# SAMA7G54D1GN0 register map
Vendor: Microchip Technology; Series: SAMA7G5; File version: 0
Registers are 32-bit, read-write, reset 0x0 unless marked. A register's access mark holds for its fields unless they carry their own. Offsets are from the block's base; [hi:lo] are bit positions; {n}, {i} and the like mark numbered series; 'fields as' and 'values as' point back to an identical list.

## ASRC — Asynchronous Sample Rate Converter
Base 0xE1610000
0x00 CR wo — Control Register
  [0] SWRST — Software Reset
    0=No effect; 1=Resets the ASRC
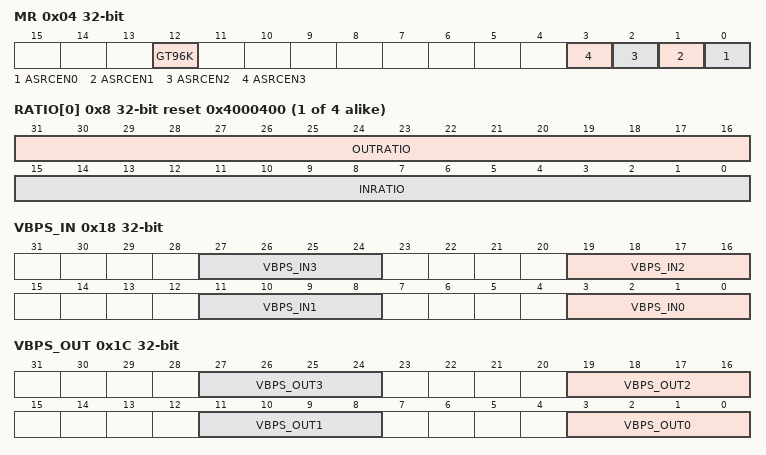
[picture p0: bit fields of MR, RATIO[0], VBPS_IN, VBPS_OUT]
0x04 MR — Mode Register
  [12] GT96K — Frequency Sampling Greater Than 96 kHz
    0=DISABLE (Up to 4 DSP with up to 96 kHz as the upper bound limit of the sampling frequency.); 1=ENABLE (Up to 2 DSP with up to 192 kHz as the upper bound limit of the sampling frequency. The number of enabled DSPs is limited to 2.)
  [n] ASRCEN{n} (n=0..3) — ASRC Stereo Channel {n} Enable
    0=DISABLE (DSPx is disabled.); 1=ENABLE (DSPx is enabled.)
{0x8+4i} RATIO[{i}] (i=0..3) reset 0x4000400 — Ratio Register of Stereo Channel x
  [31:16] OUTRATIO — Output Internal Sampling Rate Ratio
  [15:0] INRATIO — Input Internal Sampling Rate Ratio
0x18 VBPS_IN — Valid Bit Per Sample In Register
  [all] fields
    0=8_BIT (The 8 LSB of THR registers are left aligned on 24-bit data entered to the DSP. The bits [15:8] of the 24-bit data are driven by the 8 LSB of THR registers to increase the dynamic range of the data sent to DSP. The bits [7:0] are driven by 0s.); 1=16_BIT (The 16 LSB of THR registers are left aligned on 24-bit data entered to the DSP. The bits [7:0] of the 24-bit data are driven by the bits [15:8] of the THR registers to increase the dynamic range of the data sent to DSP.); 2=20_BIT (The 20 LSB of THR registers are left aligned on 24-bit data entered to the DSP. The bits [3:0] of the 24-bit data are driven by the bits [19:16] of the THR registers to increase the dynamic range of the data sent to DSP.); 3=24_BIT (The 24 LSB of THR registers are entered to the DSP.); 4=32_BIT (The 24 MSB of THR registers are entered to the DSP.); 5=10_BIT (The 10 LSB of THR registers are left aligned on 24-bit data entered to the DSP. The bits [13:4] of the 24-bit data are driven by the 10 LSB of THR registers to increase the dynamic range of the data sent to DSP. The bits [3:0] are driven by 0s.); 6=12_BIT (The 12 LSB of THR registers are left aligned on 24-bit data entered to the DSP. The bits [11:0] of the 24-bit data are driven by the bits [11:0] of the THR registers to increase the dynamic range of the data sent to DSP.); 7=14_BIT (The 14 LSB of THR registers are left aligned on 24-bit data entered to the DSP. The bits [9:0] of the 24-bit data are driven by the bits [13:4] of the THR registers to increase the dynamic range of the data sent to DSP.); 8=18_BIT (The 18 LSB of THR registers are left aligned on 24-bit data entered to the DSP. The bits [5:0] of the 24-bit data are driven by the bits [17:12] of the THR registers to increase the dynamic range of the data sent to DSP.)
  [8n+3:8n] VBPS_IN{n} (n=0..3) — Valid Bit Per Sample In of DSP {n}
0x1C VBPS_OUT — Valid Bit Per Sample Out Register
  [all] fields
    0=8_BIT (The 8 MSB of the 24-bit read from the DSP output are right-aligned on RHR.); 1=16_BIT (The 16 MSB of the 24-bit read from the DSP output are right-aligned on RHR.); 2=20_BIT (The 20 MSB of the 24-bit read from the DSP output are right-aligned on RHR.); 3=24_BIT (The 24 LSB of RHR registers are read from the 24-bit DSP output.); 4=32_BIT (The 24 MSB of RHR registers are the 24-bit output of the DSP. The 8 LSB of the RHR are driven by bits [22:15] of the DSP output.); 5=10_BIT (The 10 MSB of the 24-bit read from the DSP output are right-aligned on RHR.); 6=12_BIT (The 12 MSB of the 24-bit read from the DSP output are right-aligned on RHR.); 7=14_BIT (The 14 MSB of the 24-bit read from the DSP output are right-aligned on RHR.); 8=18_BIT (The 18 MSB of the 24-bit read from the DSP output are right-aligned on RHR.)
  [8n+3:8n] VBPS_OUT{n} (n=0..3) — Valid Bit Per Sample Out of DSP {n}
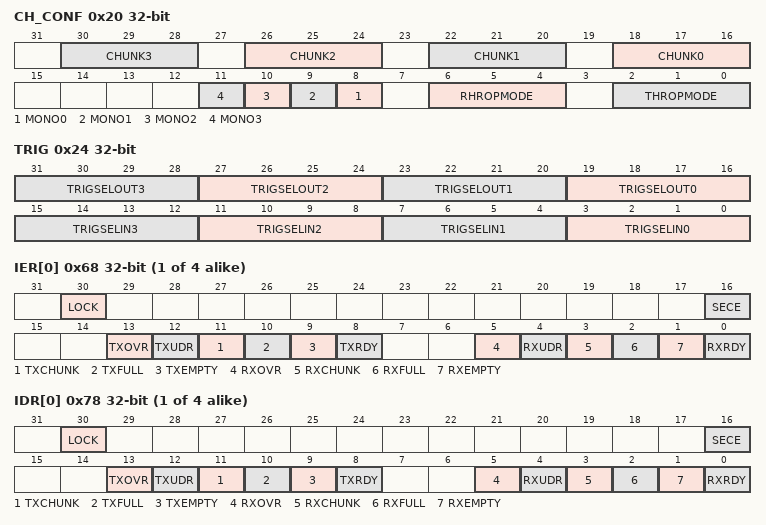
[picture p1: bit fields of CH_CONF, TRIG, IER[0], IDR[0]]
0x20 CH_CONF — Channel Configuration Register
  [4n+18:4n+16] CHUNK{n} (n=0..3) — DMA DSP {n} CHUNK Size
    0=1_DATA (The DMA chunk size must be configured to transfer 1 data for each rising edge of the trigger event.); 1=2_DATA (The DMA chunk size must be configured to transfer 2 data for each rising edge of the trigger event.); 2=4_DATA (The DMA chunk size must be configured to transfer 4 data for each rising edge of the trigger event.); 3=8_DATA (The DMA chunk size must be configured to transfer 8 data for each rising edge of the trigger event.); 4=16_DATA (The DMA chunk size must be configured to transfer 16 data for each rising edge of the trigger event.)
  [n+8] MONO{n} (n=0..3) — DSP {n} Mono Operating Mode
    0=DISABLED (DSP operates in Stereo mode.); 1=ENABLED (DSP operates in Mono mode.)
  [6:4] RHROPMODE — Receive Holding Registers Operating Mode
    0=RHRX_UPTO_2CH (The ASRC_RHRx can receive up to 2 audio streams (e.g. 1 stereo channel for each ASRC_RHR). Each ASRC_RHRx is routed on each Stereo DSP x.); 1=RHR0_UPTO_4CH (The ASRC_RHR0 can receive up to 4 audio streams (e.g. up to 2 stereo channels on ASRC_RHR0). The ARSC_RHR1 can receive up to 2 audio streams (e.g. 1 stereo channel on ASRC_RHR1). The ARSC_RHR2 can receive up to 2 audio streams (e.g. 1 stereo channel on ASRC_RHR2). ASRC_RHR3 must not be used.); 2=RHR01_UPTO_4CH (The ASRC_RHR0 can receive up to 4 audio streams (e.g. up to 2 stereo channels on ASRC_RHR0). The ASRC_RHR1 can receive up to 4 audio streams (e.g. up to 2 stereo channels on ASRC_RHR1). ASRC_RHR2 and ASRC_RHR3 must not be used.); 3=RHR0_UPTO_6CH (The ASRC_RHR0 can receive up to 6 audio streams (e.g. up to 3 stereo channels on ASRC_RHR0). The ARSC_RHR1 can receive up to 2 audio streams (e.g. 1 stereo channel on ASRC_RHR1) ASRC_RHR2 and ASRC_RHR3 must not be used.); 4=RHR0_UPTO_8CH (The ASRC_RHR0 can receive up to 8 audio streams (e.g. up to 4 stereo channels on ASRC_RHR0). ASRC_RHR1,ASRC_RHR2 and ASRC_RHR3 must not be used.)
  [2:0] THROPMODE — Transmit Holding Registers Operating Mode
    0=THRX_UPTO_2CH (The ASRC_THRx can receive up to 2 audio streams (e.g. 1 stereo channel for each ASRC_THR). Each ASRC_THRx is routed on each Stereo DSP x.); 1=THR0_UPTO_4CH (The ASRC_THR0 can receive up to 4 audio streams (e.g. up to 2 stereo channels on ASRC_THR0). The ARSC_THR1 can receive up to 2 audio streams (e.g. 1 stereo channel on ASRC_THR1). The ARSC_THR2 can receive up to 2 audio streams (e.g. 1 stereo channel on ASRC_THR2). ASRC_THR3 must not be used.); 2=THR01_UPTO_4CH (The ASRC_THR0 can receive up to 4 audio streams (e.g. up to 2 stereo channels on ASRC_THR0). The ASRC_THR1 can receive up to 4 audio streams (e.g. up to 2 stereo channels on ASRC_THR1). ASRC_THR2 and ASRC_THR3 must not be used.); 3=THR0_UPTO_6CH (The ASRC_THR0 can receive up to 6 audio streams (e.g. up to 3 stereo channels on ASRC_THR0). The ARSC_THR1 can receive up to 2 audio streams (e.g. 1 stereo channel on ASRC_THR1) ASRC_THR2 and ASRC_THR3 must not be used.); 4=THR0_UPTO_8CH (The ASRC_THR0 can receive up to 8 audio streams (e.g. up to 4 stereo channels on ASRC_THR0). ASRC_THR1,ASRC_THR2 and ASRC_RHR3 must not be used.)
0x24 TRIG — Trigger Selection Register
  [all] fields
    0=GCLKDIV (Internal trigger event, a configurable division of GCLK (see ASRC_RATIOx for divider).); 1=I2SMCC0 (Trigger event from audio peripheral.); 2=I2SMCC1 (Trigger event from audio peripheral.); 3=PDMC0 (Trigger event from audio peripheral.); 4=PDMC1 (Trigger event from audio peripheral.); 5=SSC0RX (Trigger event from audio peripheral.); 6=SSC0TX (Trigger event from audio peripheral.); 7=SSC1RX (Trigger event from audio peripheral.); 8=SSC1TX (Trigger event from audio peripheral.); 9=SPDIFTX (Trigger event from audio peripheral.); 10=SPDIFRX (Trigger event from audio peripheral.)
  [4n+19:4n+16] TRIGSELOUT{n} (n=0..3) — Output Trigger Source Selection of DSP {n}
  [4n+3:4n] TRIGSELIN{n} (n=0..3) — Input Trigger Source Selection of DSP {n}
{0x28+4i} RHR[{i}] (i=0..3) ro — Receive Holding Register x
  [31:0] DATA — Converted Data
{0x48+4i} THR[{i}] (i=0..3) wo — Transmit Holding Register x
  [31:0] DATA — Data to Convert
{0x68+4i} IER[{i}] (i=0..3) wo — Interrupt Enable Register x
  [30] LOCK — DPLL locked Interrupt Enable
  [16] SECE — Security/Safety Report Interrupt Enable
  [13] TXOVR — Transmit Over Flow Interrupt Enable
  [12] TXUDR — Transmit Under Flow Interrupt Enable
  [11] TXCHUNK — Transmit FIFO Chunk Interrupt Enable
  [10] TXFULL — Transmit FIFO Full Interrupt Enable
  [9] TXEMPTY — Transmit FIFO Empty Interrupt Enable
  [8] TXRDY — Transmit Ready Interrupt Enable
  [5] RXOVR — Receive Over Flow Interrupt Enable
  [4] RXUDR — Receive Under Flow Interrupt Enable
  [3] RXCHUNK — Receive FIFO Chunk Interrupt Enable
  [2] RXFULL — Receive FIFO Full Interrupt Enable
  [1] RXEMPTY — Receive FIFO Empty Interrupt Enable
  [0] RXRDY — Receive Ready Interrupt Enable
{0x78+4i} IDR[{i}] (i=0..3) wo — Interrupt Disable Register x
  [30] LOCK — DPLL locked Interrupt Disable
  [16] SECE — Security/Safety Report Interrupt Disable
  [13] TXOVR — Transmit Over Flow Interrupt Disable
  [12] TXUDR — Transmit Under Flow Interrupt Disable
  [11] TXCHUNK — Transmit FIFO Chunk Interrupt Disable
  [10] TXFULL — Transmit FIFO Full Interrupt Disable
  [9] TXEMPTY — Transmit FIFO Empty Interrupt Disable
  [8] TXRDY — Transmit Ready Interrupt Disable
  [5] RXOVR — Receive Over Flow Interrupt Disable
  [4] RXUDR — Receive Under Flow Interrupt Disable
  [3] RXCHUNK — Receive FIFO Chunk Interrupt Disable
  [2] RXFULL — Receive FIFO Full Interrupt Disable
  [1] RXEMPTY — Receive FIFO Empty Interrupt Disable
  [0] RXRDY — Receive Ready Interrupt Disable
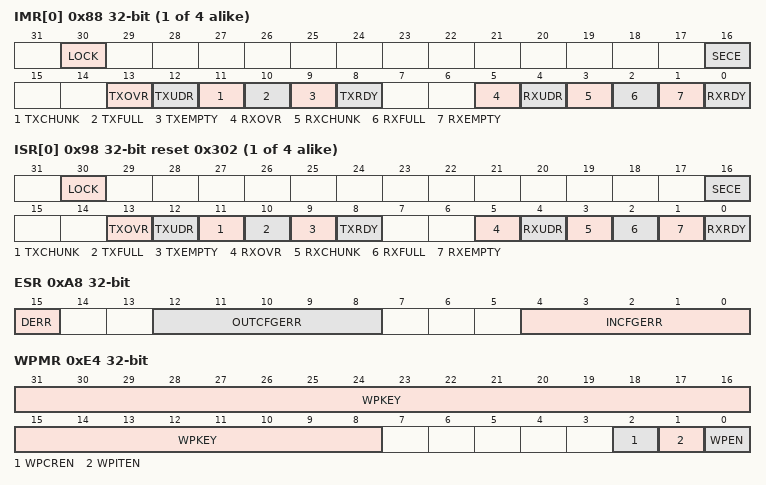
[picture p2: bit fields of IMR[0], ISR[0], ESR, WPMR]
{0x88+4i} IMR[{i}] (i=0..3) ro — Interrupt Mask Register x
  [30] LOCK — DPLL locked Interrupt Mask
  [16] SECE — Security/Safety Report Interrupt Mask
  [13] TXOVR — Transmit Over Flow Interrupt Mask
  [12] TXUDR — Transmit Under Flow Interrupt Mask
  [11] TXCHUNK — Transmit FIFO Chunk Interrupt Mask
  [10] TXFULL — Transmit FIFO Full Interrupt Mask
  [9] TXEMPTY — Transmit FIFO Empty Interrupt Mask
  [8] TXRDY — Transmit Ready Interrupt Mask
  [5] RXOVR — Receive Over Flow Interrupt Mask
  [4] RXUDR — Receive Under Flow Interrupt Mask
  [3] RXCHUNK — Receive FIFO Chunk Interrupt Mask
  [2] RXFULL — Receive FIFO Full Interrupt Mask
  [1] RXEMPTY — Receive FIFO Empty Interrupt Mask
  [0] RXRDY — Receive Ready Interrupt Mask
{0x98+4i} ISR[{i}] (i=0..3) ro reset 0x302 — Interrupt Status Register x
  [30] LOCK — DPLL Locked Interrupt Status (cleared by writing ASRC_MR.ASRCENx=0)
  [16] SECE — Security and/or Safety Event Interrupt Status (cleared on read)
    0=No security or safety event has occurred since the last read of ASRC_ISR register; 1=One or more safety or security events has occurred since the last read of ASRC_ISR. For details on the event, refer to ASRC_WPSR.
  [13] TXOVR — Transmit Over Flow Interrupt Status (cleared on read)
  [12] TXUDR — Transmit Under Flow Interrupt Status (cleared on read)
  [11] TXCHUNK — Transmit FIFO Chunk Interrupt Status (cleared automatically when the input FIFO has fewer samples than configured in ASRC_CH_CONF.CHUNKx)
  [10] TXFULL — Transmit FIFO Full Interrupt Status (cleared automatically when ASRC starts converting data)
  [9] TXEMPTY — Transmit FIFO Empty Interrupt Status (cleared when writing in ASRC_THRx)
  [8] TXRDY — Transmit Ready Interrupt Status (cleared automatically when input FIFO is full)
  [5] RXOVR — Receive Over Flow Interrupt Status (cleared on read)
  [4] RXUDR — Receive Under Flow Interrupt Status (cleared on read)
  [3] RXCHUNK — Receive FIFO Chunk Interrupt Status (cleared automatically when the output FIFO has fewer samples than configured in ASRC_CH_CONF.CHUNKx)
  [2] RXFULL — Receive FIFO Full Interrupt Status (cleared by reading ASRC_RHRx)
  [1] RXEMPTY — Receive FIFO Empty Interrupt Status (cleared automatically when ASRC has converted one sample)
  [0] RXRDY — Receive Ready Interrupt Status (cleared when output FIFO is empty after reading ASRC_RHRx)
0xA8 ESR ro — Error Status Register
  [15] DERR — DSP Overflow Error (cleared on read)
    0=No DSP overflow error detected; 1=The sampling frequency overpasses the value allowed by the configuration
  [12:8] OUTCFGERR — Output Configuration Error
    0=OUTCFG_OK (Correct configuration of ASRC_MR, ASRC_VBPS_OUT, ASRC_CH_CONF.); {v}=OP0_D{v-1}_CHK16_8M (Channel operating mode 0, DSP{v-1}: CHUNK{v-1}=16 or CHUNK{v-1}=8 and MONO{v-1}=1 is not supported.) (v=1..4); 5=OP1_D01_EN (Channel operating mode 1, DSP0/1: enable configuration is not correct (1 DSP is disabled)); 6=OP1_D01_M (Channel operating mode 1, DSP0/1: MONO0=1, MONO1=0 is not supported.); 7=OP1_D01_CHK16 (Channel operating mode 1, DSP0/1: CHUNK0=16 is not supported.); 8=OP1_D2_CHK16_8M (Channel operating mode 1, DSP2: CHUNK2=16 or CHUNK2=8 and MONO2=1 is not supported.); 9=OP1_D3_CHK16_8M (Channel operating mode 1, DSP3: CHUNK3=16 or CHUNK3=8 and MONO3=1 is not supported.); 10=OP2_D01_EN (Channel operating mode 2, DSP0/1: enable configuration is not correct (1 DSP is disabled)); 11=OP2_D01_M (Channel operating mode 2, DSP0/1: MONO0=1, MONO1=0 is not supported.); 12=OP2_D01_CHK16 (Channel operating mode 2, DSP0/1: CHUNK0=16 is not supported.); 13=OP2_D23_EN (Channel operating mode 2, DSP2/3: enable configuration is not correct (1 DSP is disabled)); 14=OP2_D23_M (Channel operating mode 2, DSP2/3: MONO2=1, MONO3=0 is not supported.); 15=OP2_D23_CHK16 (Channel operating mode 2, DSP2/3: CHUNK2=16 is not supported.); 16=OP3_D012_EN (Channel operating mode 3, DSP0/1/2: enable configuration is not correct (at least 1 DSP is disabled)); 17=OP3_D012_M (Channel operating mode 3, DSP0/1/2: mono configuration is not correct (e.g. MONO0=1, MONO1=0 or MONO2=0 is not supported).); 18=OP3_D012_CHK16 (Channel operating mode 3, DSP0/1/2: CHUNK0=16 is not supported.); 19=OP3_D3_CHK16_8M (Channel operating mode 3, DSP3: CHUNK3=16 or CHUNK3=8 and MONO3 is not supported.); 20=OP4_D0123_EN (Channel operating mode 4, DSP0/1/2/3: enable configuration is not correct (at least 1 DSP is disabled)); 21=OP4_D0123_M (Channel operating mode 4, DSP0/1/2/3: mono configuration is not correct (e.g. MONO0=1, MONO1=0 or MONO2=0 or MONO3=0 is not supported).)
  [4:0] INCFGERR — Input Configuration Error
    values as OUTCFGERR
0xE4 WPMR — Write Protection Mode Register
  [31:8] WPKEY — Write Protection Key
    0x535243=PASSWD (Writing any other value in this field aborts the write operation of the WPEN, WPITEN and WPCREN bits. Always read at 0.)
  [2] WPCREN — Write Protection Control Register Enable
    0=The write protection of control registers is disabled; 1=The write protection of control registers is enabled. Any attempt to modify the control register configuration is cancelled and leads to an error in the ASRC_WPSR register.
  [1] WPITEN — Write Protection Interrupt Enable
    0=The write protection of interrupt registers is disabled; 1=The write protection of interrupt registers is enabled. Any attempt to modify the interrupt configuration is cancelled and leads to an error in the ASRC_WPSR register.
  [0] WPEN — Write Protection Enable
    0=The write protection is disabled; 1=The write protection is enabled. All write accesses to configuration registers are canceled and generate an error in the ASRC_WPSR register
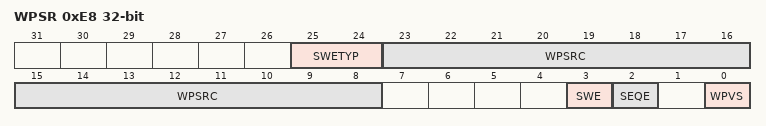
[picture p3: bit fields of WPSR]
0xE8 WPSR — Write Protection Status Register
  [25:24] SWETYP — Software Error Type (cleared on read)
    0=READ_WO (A Write-only register has been read.); 1=WRITE_RO (A write access has been performed on a Read-only register.); 2=UNDEF_RW (Access to an undefined address.)
  [23:8] WPSRC — Write Protection Source (cleared on read)
  [3] SWE — Software Control Error (cleared on read)
    0=No software error has occurred since the last read of ASRC_WPSR; 1=A software error has occurred since the last read of ASRC_WPSR. The field SWETYP details the type of software error; the associated incorrect software access is reported in the field WPVSRC (if WPVS=0).
  [2] SEQE — Internal Sequencer Error (cleared on read)
    0=No peripheral internal sequencer error has occurred since the last read of ASRC_WPSR; 1=A peripheral internal sequencer error has occurred since the last read of ASRC_WPSR
  [0] WPVS — Write Protection Violation Status (cleared on read)
    0=No write protection violation has occurred since the last read of ASRC_WPSR; 1=A write protection violation has occurred since the last read of ASRC_WPSR. If this violation is an unauthorized attempt to write a protected register, the associated violation is reported in field WPSRC.

## Notices in the file
Copyright (c) 2026 Microchip Technology Inc.
SPDX-License-Identifier: Apache-2.0
Licensed under the Apache License, Version 2.0 (the "License");
you may not use this file except in compliance with the License.
You may obtain a copy of the License at
http://www.apache.org/licenses/LICENSE-2.0
Unless required by applicable law or agreed to in writing, software
distributed under the License is distributed on an "AS IS" BASIS,
WITHOUT WARRANTIES OR CONDITIONS OF ANY KIND, either express or implied.
See the License for the specific language governing permissions and
limitations under the License.
